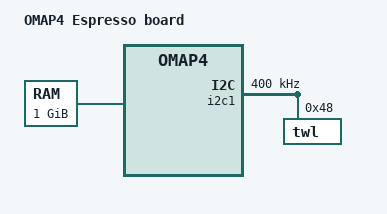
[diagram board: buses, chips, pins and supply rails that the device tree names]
/dts-v1/;

/include/ "omap443x.dtsi"
/include/ "samsung_k3pe7e700m.dtsi"

/ {
	model = "OMAP4 Espresso board";
	compatible = "ti,omap4-espresso", "ti,omap4430", "ti,omap4";

	memory {
		device_type = "memory";
		reg = <0x80000000 0x40000000>; /* 1 GB */
	};
};

&emif1 {
	cs1-used;
	device-handle = <&samsung_K3PE7E700M>;
};

&emif2 {
	cs1-used;
	device-handle = <&samsung_K3PE7E700M>;
};

&i2c1 {
	clock-frequency = <400000>;

	twl: twl@48 {
		reg = <0x48>;
		/* SPI = 0, IRQ# = 7, 4 = active high level-sensitive */
		interrupts = <0 7 4>; /* IRQ_SYS_1N cascaded to gic */
		interrupt-parent = <&gic>;
	};
};

/include/ "twl6030.dtsi"

&vana {
	regulator-always-on;
};

&usb_otg_hs {
	interface-type = <1>;
	mode = <3>;
	power = <50>;
};
